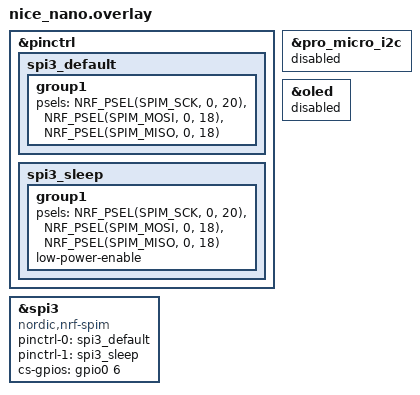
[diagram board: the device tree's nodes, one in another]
// Configuration for Corne v3/v3.6 with native 5-pin nice_view display support
// This board has the display header built-in, no adapter needed
// FINAL: SCK=P0.20, MOSI=P0.18, CS=P0.06 (standard nice_view pinout)

&pinctrl {
    spi3_default: spi3_default {
        group1 {
            psels = <NRF_PSEL(SPIM_SCK, 0, 20)>,
                    <NRF_PSEL(SPIM_MOSI, 0, 18)>,
                    <NRF_PSEL(SPIM_MISO, 0, 18)>; // MISO not used but required
        };
    };

    spi3_sleep: spi3_sleep {
        group1 {
            psels = <NRF_PSEL(SPIM_SCK, 0, 20)>,
                    <NRF_PSEL(SPIM_MOSI, 0, 18)>,
                    <NRF_PSEL(SPIM_MISO, 0, 18)>;
            low-power-enable;
        };
    };
};

nice_view_spi: &spi3 {
    compatible = "nordic,nrf-spim";
    status = "okay";
    
    pinctrl-0 = <&spi3_default>;
    pinctrl-1 = <&spi3_sleep>;
    pinctrl-names = "default", "sleep";
    
    cs-gpios = <&gpio0 6 GPIO_ACTIVE_HIGH>;
};

// Disable OLED and I2C when using nice_view
&pro_micro_i2c {
    status = "disabled";
};

&oled {
    status = "disabled";
};

// If you want RGB LEDs instead of nice_view, comment out the above
// and uncomment the configuration below:
/*
#include <dt-bindings/led/led.h>

&pinctrl {
    spi3_default: spi3_default {
        group1 {
            psels = <NRF_PSEL(SPIM_MOSI, 0, 6)>;
        };
    };

    spi3_sleep: spi3_sleep {
        group1 {
            psels = <NRF_PSEL(SPIM_MOSI, 0, 6)>;
            low-power-enable;
        };
    };
};

&spi3 {
    compatible = "nordic,nrf-spim";
    status = "okay";

    pinctrl-0 = <&spi3_default>;
    pinctrl-1 = <&spi3_sleep>;
    pinctrl-names = "default", "sleep";

    led_strip: ws2812@0 {
        compatible = "worldsemi,ws2812-spi";
        reg = <0>;
        spi-max-frequency = <4000000>;
        chain-length = <10>;
        spi-one-frame = <0x70>;
        spi-zero-frame = <0x40>;
        color-mapping = <LED_COLOR_ID_GREEN LED_COLOR_ID_RED LED_COLOR_ID_BLUE>;
    };
};

/ {
    chosen {
        zmk,underglow = &led_strip;
    };
};
*/
